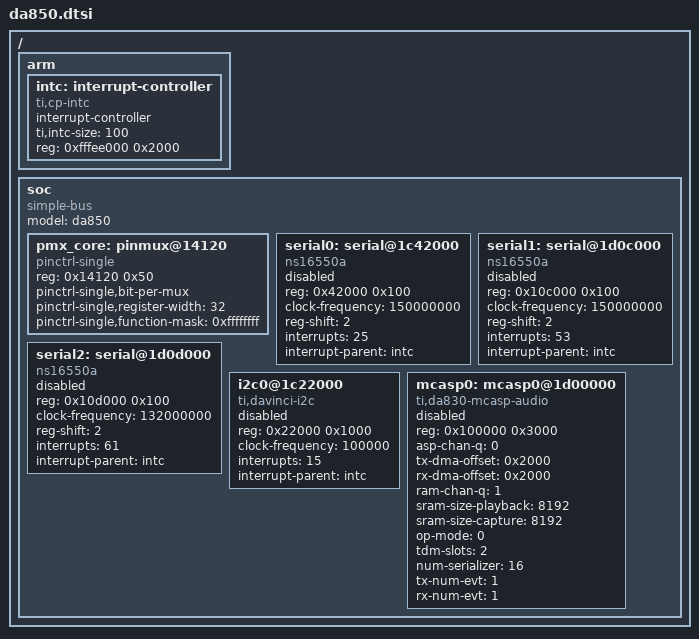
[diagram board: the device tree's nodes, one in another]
/*
 * Copyright 2012 DENX Software Engineering GmbH
 * Heiko Schocher <hs@denx.de>
 *
 * This program is free software; you can redistribute  it and/or modify it
 * under  the terms of  the GNU General  Public License as published by the
 * Free Software Foundation;  either version 2 of the  License, or (at your
 * option) any later version.
 */
/include/ "skeleton.dtsi"

/ {
	arm {
		#address-cells = <1>;
		#size-cells = <1>;
		ranges;
		intc: interrupt-controller {
			compatible = "ti,cp-intc";
			interrupt-controller;
			#interrupt-cells = <1>;
			ti,intc-size = <100>;
			reg = <0xfffee000 0x2000>;
		};
	};
	soc {
		compatible = "simple-bus";
		model = "da850";
		#address-cells = <1>;
		#size-cells = <1>;
		ranges = <0x0 0x01c00000 0x400000>;

		pmx_core:pinmux@14120 {
			compatible = "pinctrl-single";
			reg = <0x14120 0x50>;
			#address-cells = <1>;
			#size-cells = <0>;
			pinctrl-single,bit-per-mux;
			pinctrl-single,register-width = <32>;
			pinctrl-single,function-mask = <0xffffffff>;
		};
		serial0: serial@1c42000 {
			compatible = "ns16550a";
			reg = <0x42000 0x100>;
			clock-frequency = <150000000>;
			reg-shift = <2>;
			interrupts = <25>;
			interrupt-parent = <&intc>;
			status = "disabled";
		};
		serial1: serial@1d0c000 {
			compatible = "ns16550a";
			reg = <0x10c000 0x100>;
			clock-frequency = <150000000>;
			reg-shift = <2>;
			interrupts = <53>;
			interrupt-parent = <&intc>;
			status = "disabled";
		};
		serial2: serial@1d0d000 {
			compatible = "ns16550a";
			reg = <0x10d000 0x100>;
			clock-frequency = <132000000>;
			reg-shift = <2>;
			interrupts = <61>;
			interrupt-parent = <&intc>;
			status = "disabled";
		};
		i2c0@1c22000 {
			compatible = "ti,davinci-i2c";
			reg = <0x22000 0x1000>;
			clock-frequency = <100000>;
			interrupts = <15>;
			interrupt-parent = <&intc>;
			#address-cells = <1>;
			#size-cells = <0>;
			status = "disabled";
		};
		mcasp0: mcasp0@1d00000 {
			compatible = "ti,da830-mcasp-audio";
			reg = <0x100000 0x3000>;
			asp-chan-q = <0>;       /* EVENTQ_0 */
			tx-dma-offset = <0x2000>;
			rx-dma-offset = <0x2000>;
			ram-chan-q = <1>;       /* EVENTQ_1 */
			sram-size-playback = <8192>;
			sram-size-capture = <8192>;
			op-mode = <0>;          /* MCASP_IIS_MODE */
			tdm-slots = <2>;
			num-serializer = <16>;
			tx-num-evt = <1>;
			rx-num-evt = <1>;
			status = "disabled";
		};
	};
};
